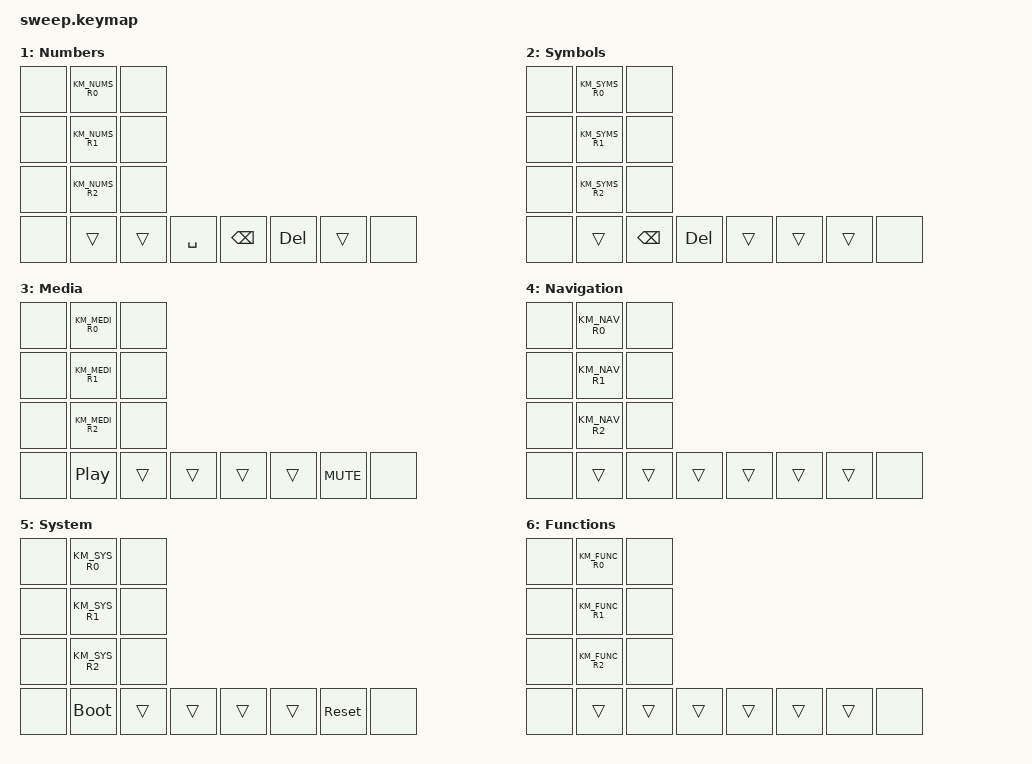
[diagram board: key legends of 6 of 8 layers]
/*
 * Sweep Pro keymap — 44 bindings per layer to match universal dongle layout.
 * Dummy &none at outer columns (0, 11) and thumb positions RC(3,1), RC(3,10)
 * keep binding indices aligned with the dongle's 12-column transform.
 *
 * Physical layout: 10+10+10+6 = 36 real keys
 *   Rows 0-2:  10 inner keys, plus 2 dummy &none at each end
 *   Thumbs:    6 inner keys, plus 2 dummy &none at RC(3,1) and RC(3,10)
 *
 * Encoder-adjacent outer thumbs (RC(3,3), RC(3,8)):
 *   Base layer:  &lt MEDIA C_MUTE (left), &lt SYSTEM C_PP (right)
 *   Media layer: C_PP (left), C_MUTE (right) — swapped
 *   System layer: &bootloader (left), &sys_reset (right)
 *   All other layers: &trans → falls through to base
 *
 * BSPC/DEL without encoder clicks:
 *   Hold NUMBERS (NUM/TAB) + tap SYM/ESC (right-inner-2) = DEL
 *   Hold SYMBOLS (SYM/ESC) + tap NAV/SPC (left-inner-2)  = BSPC
 */

// Copyright (c) 2022 The ZMK Contributors
// SPDX-License-Identifier: MIT

#define ZMK_POINTING_DEFAULT_MOVE_VAL 5000
#define ZMK_POINTING_DEFAULT_SCRL_VAL 40

#include <behaviors.dtsi>
#include <dt-bindings/zmk/keys.h>
#include <dt-bindings/zmk/bt.h>
#include <dt-bindings/zmk/outputs.h>
#include <dt-bindings/zmk/pointing.h>
#include <dt-bindings/zmk/ext_power.h>
#include <dt-bindings/zmk/rgb.h>
#include <dt-bindings/zmk/reset.h>
#include "../../../behaviors/character_map.dtsi"
#include "../../../behaviors/homerow_mods.dtsi"
#include "../../../behaviors/report.dtsi"
#include "../../../behaviors/keymap_layers.h"

// Sweep adds MOUSE layer
#define MOUSE 7

&sensors {
    left_encoder  { triggers-per-rotation = <15>; };
    right_encoder { triggers-per-rotation = <45>; };
};

&soft_off { hold-time-ms = <5000>; };
&lt       { tapping-term-ms = <200>; quick_tap_ms = <200>; };

/ {
    KM_COND_LAYERS

    keymap {
        compatible = "zmk,keymap";

        base_layer {
            display-name = "Base";
            bindings = <
                &none  KM_BASE_R0  &none
                &none  KM_BASE_R1  &none
                &none  KM_BASE_R2  &none
                &none  &lt MEDIA C_MUTE  KM_MID_T  &lt SYSTEM C_PP  &none
            >;
            // Left slot: arrows (CW = right, CCW = left) — for future builds.
            // Right slot (mounted): PgUp (CW) / PgDn (CCW).
            sensor-bindings = <&inc_dec_kp RIGHT LEFT &inc_dec_kp PG_UP PG_DN>;
        };

        numbers_layer {
            display-name = "Numbers";
            bindings = <
                &none  KM_NUMS_R0  &none
                &none  KM_NUMS_R1  &none
                &none  KM_NUMS_R2  &none
                //       ENC-L  NUM/TAB  NAV/SPC  FUN/RET  SYM/ESC→DEL  ENC-R
                &none  &trans  &trans  &kp SPACE  &kp BSPC  &kp DEL  &trans  &none
            >;
            // Right encoder only (left slot cleared).
            sensor-bindings = <&sensor_none 0 0 &inc_dec_kp LC(LEFT) LC(RIGHT)>;
        };

        symbols_layer {
            display-name = "Symbols";
            bindings = <
                &none  KM_SYMS_R0  &none
                &none  KM_SYMS_R1  &none
                &none  KM_SYMS_R2  &none
                //       ENC-L→BSPC  NUM/TAB→DEL  NAV/SPC  FUN/RET  SYM/ESC  ENC-R
                &none  &trans  &kp BSPC  &kp DEL  &trans  &trans  &trans  &none
            >;
            // Left encoder only (right slot cleared).
            sensor-bindings = <&inc_dec_kp C_BRI_DN C_BRI_UP &sensor_none 0 0>;
        };

        media_layer {
            display-name = "Media";
            bindings = <
                &none  KM_MEDI_R0  &none
                &none  KM_MEDI_R1  &none
                &none  KM_MEDI_R2  &none
                //       ENC-L  NUM/TAB  NAV/SPC  FUN/RET  SYM/ESC  ENC-R
                &none  &kp C_PP  &trans  &trans  &trans  &trans  &kp C_MUTE  &none
            >;
            sensor-bindings = <&sensor_none 0 0 &inc_dec_kp C_PREV C_NEXT>;
        };

        nav_layer {
            display-name = "Navigation";
            bindings = <
                &none  KM_NAV_R0  &none
                &none  KM_NAV_R1  &none
                &none  KM_NAV_R2  &none
                &none  &trans  &trans  &trans  &trans  &trans  &trans  &none
            >;
            sensor-bindings = <&sensor_none 0 0 &inc_dec_kp LEFT RIGHT>;
        };

        system_layer {
            display-name = "System";
            bindings = <
                &none  KM_SYS_R0  &none
                &none  KM_SYS_R1  &none
                &none  KM_SYS_R2  &none
                //       ENC-L        NUM/TAB  NAV/SPC  FUN/RET  SYM/ESC  ENC-R
                &none  &bootloader  &trans  &trans  &trans  &trans  &sys_reset  &none
            >;
            // Left encoder only (right slot cleared).
            sensor-bindings = <&inc_dec_kp C_VOL_DN C_VOL_UP &sensor_none 0 0>;
        };

        functions_layer {
            display-name = "Functions";
            bindings = <
                &none  KM_FUNC_R0  &none
                &none  KM_FUNC_R1  &none
                &none  KM_FUNC_R2  &none
                &none  &trans  &trans  &trans  &trans  &trans  &trans  &none
            >;
            sensor-bindings = <&inc_dec_kp C_VOL_DN C_VOL_UP &sensor_none 0 0>;
        };

        // Sweep-exclusive: cirque trackpad mouse layer
        mouse_layer {
            display-name = "Mouse";
            bindings = <
                &none  &tog MOUSE  &mkp MB4  &mkp MCLK  &mkp MB5  &trans    &msc SCRL_LEFT &msc SCRL_DOWN &msc SCRL_UP &msc SCRL_RIGHT &tog MOUSE  &none
                &none  &trans      &trans    &trans      &trans    &trans    &mmv MOVE_LEFT &mmv MOVE_DOWN &mmv MOVE_UP &mmv MOVE_RIGHT &trans      &none
                &none  &trans      &trans    &trans      &trans    &trans    &trans         &mkp MB4       &mkp MCLK    &mkp MB5        &trans      &none
                &none  &trans      &kp SPACE &kp LSHFT   &mkp LCLK  &mkp RCLK &trans  &none
            >;
            sensor-bindings = <&inc_dec_kp PG_DN PG_UP &inc_dec_kp LEFT RIGHT>;
        };
    };
};
